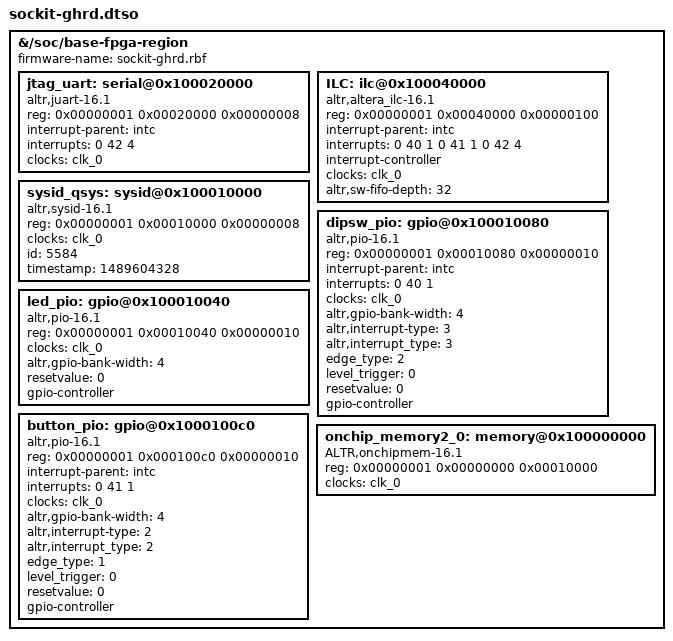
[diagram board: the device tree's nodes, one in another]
/*
 * This devicetree is generated by sopc2dts version rel_14.0_RC3-38-g6cfd69a on Tue Mar 28 12:21:18 EDT 2017
 * Sopc2dts is written by Walter Goossens <waltergoossens@home.nl>
 * in cooperation with the nios2 community <nios2-dev@lists.rocketboards.org>
 */
/dts-v1/ /plugin/;
/include/ "sockit-ghrd.dtsi"

/ {

	fragment@0 {
		target-path = "/soc/base-fpga-region";

		__overlay__ {
			firmware-name = "sockit-ghrd.rbf";
			#address-cells = <2>;
			#size-cells = <1>;
			ranges = <0x00000000 0x00000000 0xc0000000 0x20000000>,
				<0x00000001 0x00000000 0xff200000 0x00200000>;

			jtag_uart: serial@0x100020000 {
				compatible = "altr,juart-16.1", "altr,juart-1.0";
				reg = <0x00000001 0x00020000 0x00000008>;
				interrupt-parent = <&intc>;
				interrupts = <0 42 4>;
				clocks = <&clk_0>;
			}; //end serial@0x100020000 (jtag_uart)

			ILC: ilc@0x100040000 {
				compatible = "altr,altera_ilc-16.1", "altr,ilc-1.0";
				reg = <0x00000001 0x00040000 0x00000100>;
				interrupt-parent = <&intc>;
				interrupts = <0 40 1 0 41 1 0 42 4>;
				interrupt-names = "dipsw_pio", "button_pio", "jtag_uart";
				interrupt-controller;
				#interrupt-cells = <1>;
				clocks = <&clk_0>;
				altr,sw-fifo-depth = <32>;	/* embeddedsw.dts.params.altr,sw-fifo-depth type NUMBER */
			}; //end ilc@0x100040000 (ILC)

			sysid_qsys: sysid@0x100010000 {
				compatible = "altr,sysid-16.1", "altr,sysid-1.0";
				reg = <0x00000001 0x00010000 0x00000008>;
				clocks = <&clk_0>;
				id = <5584>;	/* embeddedsw.dts.params.id type NUMBER */
				timestamp = <1489604328>;	/* embeddedsw.dts.params.timestamp type NUMBER */
			}; //end sysid@0x100010000 (sysid_qsys)

			dipsw_pio: gpio@0x100010080 {
				compatible = "altr,pio-16.1", "altr,pio-1.0";
				reg = <0x00000001 0x00010080 0x00000010>;
				interrupt-parent = <&intc>;
				interrupts = <0 40 1>;
				clocks = <&clk_0>;
				altr,gpio-bank-width = <4>;	/* embeddedsw.dts.params.altr,gpio-bank-width type NUMBER */
				altr,interrupt-type = <3>;	/* embeddedsw.dts.params.altr,interrupt-type type NUMBER */
				altr,interrupt_type = <3>;	/* embeddedsw.dts.params.altr,interrupt_type type NUMBER */
				edge_type = <2>;	/* embeddedsw.dts.params.edge_type type NUMBER */
				level_trigger = <0>;	/* embeddedsw.dts.params.level_trigger type NUMBER */
				resetvalue = <0>;	/* embeddedsw.dts.params.resetvalue type NUMBER */
				#gpio-cells = <2>;
				gpio-controller;
			}; //end gpio@0x100010080 (dipsw_pio)

			led_pio: gpio@0x100010040 {
				compatible = "altr,pio-16.1", "altr,pio-1.0";
				reg = <0x00000001 0x00010040 0x00000010>;
				clocks = <&clk_0>;
				altr,gpio-bank-width = <4>;	/* embeddedsw.dts.params.altr,gpio-bank-width type NUMBER */
				resetvalue = <0>;	/* embeddedsw.dts.params.resetvalue type NUMBER */
				#gpio-cells = <2>;
				gpio-controller;
			}; //end gpio@0x100010040 (led_pio)

			button_pio: gpio@0x1000100c0 {
				compatible = "altr,pio-16.1", "altr,pio-1.0";
				reg = <0x00000001 0x000100c0 0x00000010>;
				interrupt-parent = <&intc>;
				interrupts = <0 41 1>;
				clocks = <&clk_0>;
				altr,gpio-bank-width = <4>;	/* embeddedsw.dts.params.altr,gpio-bank-width type NUMBER */
				altr,interrupt-type = <2>;	/* embeddedsw.dts.params.altr,interrupt-type type NUMBER */
				altr,interrupt_type = <2>;	/* embeddedsw.dts.params.altr,interrupt_type type NUMBER */
				edge_type = <1>;	/* embeddedsw.dts.params.edge_type type NUMBER */
				level_trigger = <0>;	/* embeddedsw.dts.params.level_trigger type NUMBER */
				resetvalue = <0>;	/* embeddedsw.dts.params.resetvalue type NUMBER */
				#gpio-cells = <2>;
				gpio-controller;
			}; //end gpio@0x1000100c0 (button_pio)

			onchip_memory2_0: memory@0x100000000 {
				device_type = "memory";
				compatible = "ALTR,onchipmem-16.1";
				reg = <0x00000001 0x00000000 0x00010000>;
				clocks = <&clk_0>;
			}; //end memory@0x100000000 (onchip_memory2_0)
		}; //end __overlay__
	}; //end fragment@0
}; //end /
